VERSION ""

NS_ :

BS_:

BU_: New_Node_1

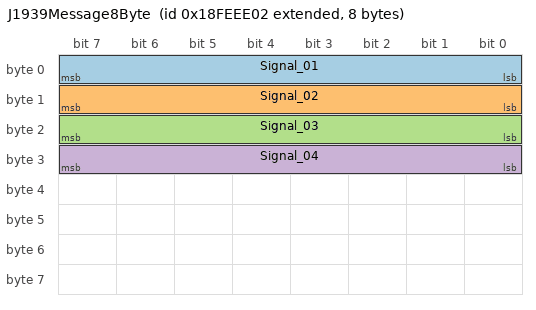
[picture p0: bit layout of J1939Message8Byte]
BO_ 2566843906 J1939Message8Byte: 8 New_Node_1
 SG_ Signal_01 : 0|8@1+ (1,0) [0|255] "Num" Vector__XXX
 SG_ Signal_02 : 8|8@1+ (1,0) [0|255] "Num" Vector__XXX
 SG_ Signal_03 : 16|8@1+ (1,0) [0|255] "Num" Vector__XXX
 SG_ Signal_04 : 24|8@1+ (1,0) [0|255] "Num" Vector__XXX

BO_ 2566843907 J1938Message1Byte: 1 New_Node_1
 SG_ Signal_05 : 0|8@1+ (1,0) [0|255] "Num" Vector__XXX

CM_ BO_ 2566843906 "J1939 Message";
CM_ SG_ 2566843906 Signal_01 "Signal 01 of J1939 message";
CM_ SG_ 2566843906 Signal_02 "Signal 02 of J1939 message";
CM_ SG_ 2566843906 Signal_03 "Signal 03 of J1939 message";
CM_ SG_ 2566843906 Signal_04 "Signal 04 of J1939 message";
CM_ BO_ 2566843907 "J1939 Message";
CM_ SG_ 2566843907 Signal_05 "Signal 01 of J1939 message";
BA_DEF_ SG_  "SPN" INT 0 524287;
BA_DEF_ BO_  "VFrameFormat" ENUM  "StandardCAN","ExtendedCAN","reserved","J1939PG";
BA_DEF_  "BusType" STRING ;
BA_DEF_DEF_  "SPN" 0;
BA_DEF_DEF_  "VFrameFormat" "J1939PG";
BA_DEF_DEF_  "BusType" "";
BA_ "BusType" "CAN";
BA_ "SPN" SG_ 2566843906 Signal_01 1001;
BA_ "SPN" SG_ 2566843906 Signal_02 1002;
BA_ "SPN" SG_ 2566843906 Signal_03 1003;
BA_ "SPN" SG_ 2566843906 Signal_04 1004;
BA_ "SPN" SG_ 2566843907 Signal_05 1005;
